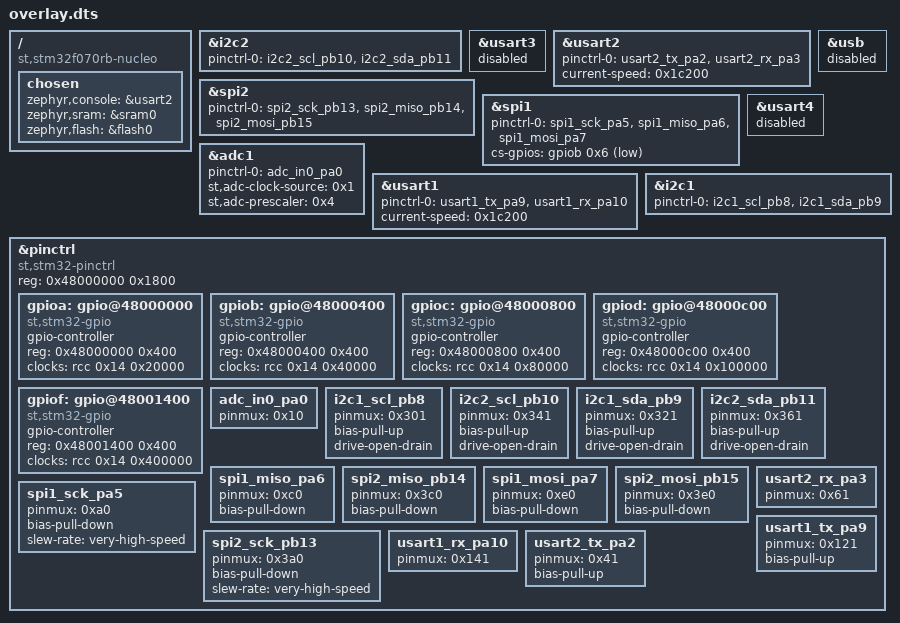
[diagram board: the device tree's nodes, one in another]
/ {
	compatible = "st,stm32f070rb-nucleo";
	chosen {
		zephyr,console = &usart2;
		zephyr,sram = &sram0;
		zephyr,flash = &flash0;
	};
};
&i2c2{
	status = "okay";
	pinctrl-0 = < &i2c2_scl_pb10 &i2c2_sda_pb11 >;
	pinctrl-names = "default";
};
&usart3{
	status = "disabled";
};
&usart2{
	status = "okay";
	pinctrl-0 = < &usart2_tx_pa2 &usart2_rx_pa3 >;
	pinctrl-names = "default";
	current-speed = < 0x1c200 >;
};
&spi2{
	status = "okay";
	pinctrl-0 = < &spi2_sck_pb13 &spi2_miso_pb14 &spi2_mosi_pb15 >;
	pinctrl-names = "default";
};
&usb{
	status = "disabled";
};
&spi1{
	status = "okay";
	pinctrl-0 = < &spi1_sck_pa5 &spi1_miso_pa6 &spi1_mosi_pa7 >;
	pinctrl-names = "default";
	cs-gpios = < &gpiob 0x6 0x11 >;
};
&usart4{
	status = "disabled";
};
&adc1{
	status = "okay";
	pinctrl-0 = < &adc_in0_pa0 >;
	pinctrl-names = "default";
	st,adc-clock-source = < 0x1 >;
	st,adc-prescaler = < 0x4 >;
};
&usart1{
	status = "okay";
	pinctrl-0 = < &usart1_tx_pa9 &usart1_rx_pa10 >;
	pinctrl-names = "default";
	current-speed = < 0x1c200 >;
};
&i2c1{
	status = "okay";
	pinctrl-0 = < &i2c1_scl_pb8 &i2c1_sda_pb9 >;
	pinctrl-names = "default";
};
&pinctrl{
	compatible = "st,stm32-pinctrl";
	#address-cells = < 0x1 >;
	#size-cells = < 0x1 >;
	reg = < 0x48000000 0x1800 >;
	gpioa: gpio@48000000 {
		compatible = "st,stm32-gpio";
		gpio-controller;
		#gpio-cells = < 0x2 >;
		reg = < 0x48000000 0x400 >;
		clocks = < &rcc 0x14 0x20000 >;
	};
	gpiob: gpio@48000400 {
		compatible = "st,stm32-gpio";
		gpio-controller;
		#gpio-cells = < 0x2 >;
		reg = < 0x48000400 0x400 >;
		clocks = < &rcc 0x14 0x40000 >;
	};
	gpioc: gpio@48000800 {
		compatible = "st,stm32-gpio";
		gpio-controller;
		#gpio-cells = < 0x2 >;
		reg = < 0x48000800 0x400 >;
		clocks = < &rcc 0x14 0x80000 >;
	};
	gpiod: gpio@48000c00 {
		compatible = "st,stm32-gpio";
		gpio-controller;
		#gpio-cells = < 0x2 >;
		reg = < 0x48000c00 0x400 >;
		clocks = < &rcc 0x14 0x100000 >;
	};
	gpiof: gpio@48001400 {
		compatible = "st,stm32-gpio";
		gpio-controller;
		#gpio-cells = < 0x2 >;
		reg = < 0x48001400 0x400 >;
		clocks = < &rcc 0x14 0x400000 >;
	};
	adc_in0_pa0: adc_in0_pa0 {
		pinmux = < 0x10 >;
	};
	i2c1_scl_pb8: i2c1_scl_pb8 {
		pinmux = < 0x301 >;
		bias-pull-up;
		drive-open-drain;
	};
	i2c2_scl_pb10: i2c2_scl_pb10 {
		pinmux = < 0x341 >;
		bias-pull-up;
		drive-open-drain;
	};
	i2c1_sda_pb9: i2c1_sda_pb9 {
		pinmux = < 0x321 >;
		bias-pull-up;
		drive-open-drain;
	};
	i2c2_sda_pb11: i2c2_sda_pb11 {
		pinmux = < 0x361 >;
		bias-pull-up;
		drive-open-drain;
	};
	spi1_miso_pa6: spi1_miso_pa6 {
		pinmux = < 0xc0 >;
		bias-pull-down;
	};
	spi2_miso_pb14: spi2_miso_pb14 {
		pinmux = < 0x3c0 >;
		bias-pull-down;
	};
	spi1_mosi_pa7: spi1_mosi_pa7 {
		pinmux = < 0xe0 >;
		bias-pull-down;
	};
	spi2_mosi_pb15: spi2_mosi_pb15 {
		pinmux = < 0x3e0 >;
		bias-pull-down;
	};
	spi1_sck_pa5: spi1_sck_pa5 {
		pinmux = < 0xa0 >;
		bias-pull-down;
		slew-rate = "very-high-speed";
	};
	spi2_sck_pb13: spi2_sck_pb13 {
		pinmux = < 0x3a0 >;
		bias-pull-down;
		slew-rate = "very-high-speed";
	};
	usart1_rx_pa10: usart1_rx_pa10 {
		pinmux = < 0x141 >;
	};
	usart2_rx_pa3: usart2_rx_pa3 {
		pinmux = < 0x61 >;
	};
	usart1_tx_pa9: usart1_tx_pa9 {
		pinmux = < 0x121 >;
		bias-pull-up;
	};
	usart2_tx_pa2: usart2_tx_pa2 {
		pinmux = < 0x41 >;
		bias-pull-up;
	};
};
